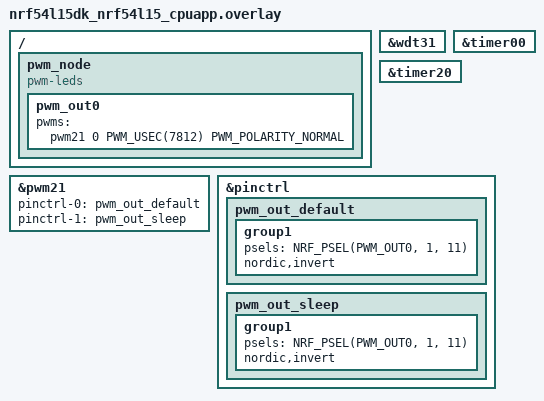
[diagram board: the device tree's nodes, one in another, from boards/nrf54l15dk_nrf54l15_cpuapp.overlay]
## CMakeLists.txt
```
#
# Copyright (c) 2018 Nordic Semiconductor
#
# SPDX-License-Identifier: LicenseRef-Nordic-5-Clause
#
cmake_minimum_required(VERSION 3.20.0)

find_package(Zephyr REQUIRED HINTS $ENV{ZEPHYR_BASE})
project(lesson_4_e2_solution)

set(SOURCES src/main.c)

if (CONFIG_PWM)
    list(APPEND SOURCES src/periph_pwm.c)
endif()

if( CONFIG_NRFX_PWM_GRTC )
    list(APPEND SOURCES src/grtc_pwm.c)
endif()

if( CONFIG_WATCHDOG )
    list(APPEND SOURCES src/wdg_conf.c)
endif()

if(CONFIG_NRFX_TIMER)
    list(APPEND SOURCES src/timer_conf.c)
endif(CONFIG_NRFX_TIMER)

target_include_directories(app PRIVATE inc)
target_sources(app PRIVATE ${SOURCES} )
```

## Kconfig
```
#
# Copyright (c) 2018 Nordic Semiconductor
#
# SPDX-License-Identifier: LicenseRef-Nordic-5-Clause
#

source "Kconfig.zephyr"

menu "Lesson 4 Exercise 2 config"

config PWM_DUTY_CYCLE
	depends on  PWM || NRFX_PWM_GRTC
	int "PWM duty cycle in %"
	default 25

config NRFX_PWM_GRTC
	bool "Use GRTC for PWM"
	default n

config NRFX_TIMER00_1MHz
	bool "Use TIMER00 at 1MHz"
	default n
	select NRFX_TIMER

config NRFX_TIMER00_128MHz
	bool "Use TIMER00 at 128MHz"
	default n
	select NRFX_TIMER

config NRFX_TIMER20_1MHz
	bool "Use TIMER20 at 1MHz"
	default n
	select NRFX_TIMER

endmenu
```

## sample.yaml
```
sample:
  description: Designing Low Power Bluetooth LE devices Lesson 4 Exercise 2
  name: Low Power Bluetooth LE devices - Lesson 4 Exercise 2 

common: 
    sysbuild: true
    build_only: true

    integration_platforms:
      - nrf54l15dk/nrf54l15/cpuapp
      - nrf54l15dk/nrf54l10/cpuapp
      - nrf54l15dk/nrf54l05/cpuapp
      - nrf54lm20dk/nrf54lm20a/cpuapp
      - nrf54lm20dk/nrf54lm20b/cpuapp
      - nrf54ls05dk/nrf54ls05b/cpuapp
      - nrf54lv10dk/nrf54lv10a/cpuapp
      - nrf54lc10dk/nrf54lc10a/cpuapp
    platform_allow:
      - nrf54l15dk/nrf54l15/cpuapp
      - nrf54l15dk/nrf54l10/cpuapp
      - nrf54l15dk/nrf54l05/cpuapp
      - nrf54lm20dk/nrf54lm20a/cpuapp
      - nrf54lm20dk/nrf54lm20b/cpuapp
      - nrf54ls05dk/nrf54ls05b/cpuapp
      - nrf54lv10dk/nrf54lv10a/cpuapp
      - nrf54lc10dk/nrf54lc10a/cpuapp

tests:
  l4.e2.sol: {} 
  
```

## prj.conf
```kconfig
#
# Copyright (c) 2018 Nordic Semiconductor
#
# SPDX-License-Identifier: LicenseRef-Nordic-5-Clause
#

# Logging
CONFIG_LOG=n
CONFIG_SERIAL=n
CONFIG_UART_CONSOLE=n

# Floating Point Unit
CONFIG_FPU=y

# Memory
CONFIG_MAIN_STACK_SIZE=4096
CONFIG_HEAP_MEM_POOL_SIZE=2048
CONFIG_SYSTEM_WORKQUEUE_STACK_SIZE=2048

CONFIG_BT=y
CONFIG_BT_PERIPHERAL=y
CONFIG_BT_DEVICE_NAME="DevAcademy_L4E2"
CONFIG_BT_MAX_CONN=1
CONFIG_BT_MAX_PAIRED=1
CONFIG_BT_USER_PHY_UPDATE=y

# Enable the NUS service
CONFIG_BT_NUS=y
CONFIG_BT_NUS_SECURITY_ENABLED=n

# Enable bonding
CONFIG_BT_SETTINGS=y
CONFIG_FLASH=y
CONFIG_FLASH_PAGE_LAYOUT=y
CONFIG_FLASH_MAP=y
CONFIG_BT_RX_STACK_SIZE=2048
CONFIG_BT_BUF_CMD_TX_COUNT=2

# STEP 4.1 - Enable automatic update of connection parameters
CONFIG_BT_GAP_AUTO_UPDATE_CONN_PARAMS=y

# STEP 4.2 - Set the preferred connection parameters
CONFIG_BT_PERIPHERAL_PREF_MIN_INT=800
CONFIG_BT_PERIPHERAL_PREF_MAX_INT=800
CONFIG_BT_PERIPHERAL_PREF_LATENCY=0
CONFIG_BT_PERIPHERAL_PREF_TIMEOUT=400

# STEP 7.1 - Update data length and MTU
CONFIG_BT_GATT_CLIENT=y
CONFIG_BT_USER_DATA_LEN_UPDATE=y
CONFIG_BT_CTLR_DATA_LENGTH_MAX=251
CONFIG_BT_BUF_ACL_TX_SIZE=251
CONFIG_BT_BUF_ACL_RX_SIZE=251
CONFIG_BT_L2CAP_TX_MTU=247
```

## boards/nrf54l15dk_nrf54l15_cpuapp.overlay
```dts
/ { pwm_node:pwm_node{
        compatible= "pwm-leds";
        pwm_out0: pwm_out0 {
            pwms = <&pwm21 0 PWM_USEC(7812) PWM_POLARITY_NORMAL>;
        };
};
};

&wdt31 {
	status = "okay";
};

 &timer00 {
    status = "okay";
};

 &timer20 {
    status = "okay";
};


&pwm21 {
    status = "okay";
    pinctrl-0 = <&pwm_out_default>;
    pinctrl-1 = <&pwm_out_sleep>;
    pinctrl-names = "default", "sleep";
};

&pinctrl {
    pwm_out_default: pwm_out_default {
        group1 {
            psels = <NRF_PSEL(PWM_OUT0, 1, 11)>;
            nordic,invert;
        };
    };

    pwm_out_sleep: pwm_out_sleep {
        group1 {
            psels = <NRF_PSEL(PWM_OUT0, 1, 11)>;
            nordic,invert;
        };
    };
};
```

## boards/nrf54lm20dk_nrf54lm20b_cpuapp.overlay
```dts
/*
 * Copyright (c) 2025 Nordic Semiconductor ASA
 *
 * SPDX-License-Identifier: LicenseRef-Nordic-5-Clause
 */

/ {
    chosen {
        nordic,nus-uart = &uart20;
    };
};
```

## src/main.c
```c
/*
 * Copyright (c) 2018 Nordic Semiconductor ASA
 *
 * SPDX-License-Identifier: LicenseRef-Nordic-5-Clause
 */

#include <zephyr/types.h>
#include <stddef.h>
#include <string.h>
#include <errno.h>
#include <zephyr/sys/printk.h>
#include <zephyr/sys/byteorder.h>
#include <zephyr/kernel.h>

#include <zephyr/device.h>
#include <zephyr/drivers/gpio.h>
#include <soc.h>

#include <zephyr/bluetooth/bluetooth.h>
#include <zephyr/bluetooth/hci.h>
#include <zephyr/bluetooth/conn.h>
#include <zephyr/bluetooth/uuid.h>
#include <zephyr/bluetooth/gatt.h>

#include <bluetooth/services/lbs.h>

#include <zephyr/settings/settings.h>

#if CONFIG_WATCHDOG
    #include <zephyr/drivers/watchdog.h>
#endif

#if CONFIG_NRFX_TIMER
    #include <nrfx_timer.h>
    #define TIMER_INST_IDX 20
    static nrfx_timer_t timer_inst = NRFX_TIMER_INSTANCE(NRF_TIMER_INST_GET(TIMER_INST_IDX));

#endif  

#if CONFIG_NRFX_PWM_GRTC
    #include <nrfx_grtc.h>
    #include <hal/nrf_gpio.h>
    #define GRTC_PWM_PIN 0x03
    #define GRTC_PWM_PULSE (255/4) 
#endif

#if CONFIG_PWM
    #include <zephyr/drivers/pwm.h>
    #define PWM_PERIOD  PWM_USEC(7812)
    #define PWM_PULSE  ( ( PWM_PERIOD) / 4 ) 
    static const struct pwm_dt_spec pwm_led0 = PWM_DT_SPEC_GET(DT_NODELABEL(pwm_out0));
#endif

#define DEVICE_NAME             CONFIG_BT_DEVICE_NAME
#define DEVICE_NAME_LEN         (sizeof(DEVICE_NAME) - 1)

#define RANDOM_BYTES_COUNT      16

#define RUN_STATUS_LED          DK_LED1
#define CON_STATUS_LED          DK_LED2
#define RUN_LED_BLINK_INTERVAL  1000

#define USER_LED                DK_LED3

#define USER_BUTTON             DK_BTN1_MSK

#define BT_LE_ADV_CONN_1000                                                                      \
    BT_LE_ADV_PARAM(BT_LE_ADV_OPT_CONN, BT_GAP_ADV_SLOW_INT_MIN, BT_GAP_ADV_SLOW_INT_MIN,  \
            NULL)

static bool app_button_state;
static struct k_work adv_work;

static const struct bt_data ad[] = {
    BT_DATA_BYTES(BT_DATA_FLAGS, (BT_LE_AD_GENERAL | BT_LE_AD_NO_BREDR)),
    BT_DATA(BT_DATA_NAME_COMPLETE, DEVICE_NAME, DEVICE_NAME_LEN),
};

static const struct bt_data sd[] = {
    BT_DATA_BYTES(BT_DATA_UUID128_ALL, BT_UUID_LBS_VAL),
};

static void adv_work_handler(struct k_work *work)
{
    int err = bt_le_adv_start(BT_LE_ADV_CONN_1000, ad, ARRAY_SIZE(ad), sd, ARRAY_SIZE(sd));

    if (err) {
        printk("Advertising failed to start (err %d)\n", err);
        return;
    }

    printk("Advertising successfully started\n");
}

static void advertising_start(void)
{
    k_work_submit(&adv_work);
}

static void connected(struct bt_conn *conn, uint8_t err)
{
    if (err) {
        printk("Connection failed, err 0x%02x %s\n", err, bt_hci_err_to_str(err));
        return;
    }

    printk("Connected\n");
}

static void disconnected(struct bt_conn *conn, uint8_t reason)
{
    printk("Disconnected, reason 0x%02x %s\n", reason, bt_hci_err_to_str(reason));
}


static void recycled_cb(void)
{
    printk("Connection object available from previous conn. Disconnect is complete!\n");
    advertising_start();
}

#ifdef CONFIG_BT_LBS_SECURITY_ENABLED
static void security_changed(struct bt_conn *conn, bt_security_t level,
                 enum bt_security_err err)
{
    char addr[BT_ADDR_LE_STR_LEN];

    bt_addr_le_to_str(bt_conn_get_dst(conn), addr, sizeof(addr));

    if (!err) {
        printk("Security changed: %s level %u\n", addr, level);
    } else {
        printk("Security failed: %s level %u err %d %s\n", addr, level, err,
               bt_security_err_to_str(err));
    }
}
#endif

BT_CONN_CB_DEFINE(conn_callbacks) = {
    .connected        = connected,
    .disconnected     = disconnected,
    .recycled         = recycled_cb,
#ifdef CONFIG_BT_LBS_SECURITY_ENABLED
    .security_changed = security_changed,
#endif
};

#if defined(CONFIG_BT_LBS_SECURITY_ENABLED)
static void auth_passkey_display(struct bt_conn *conn, unsigned int passkey)
{
    char addr[BT_ADDR_LE_STR_LEN];

    bt_addr_le_to_str(bt_conn_get_dst(conn), addr, sizeof(addr));

    printk("Passkey for %s: %06u\n", addr, passkey);
}

static void auth_cancel(struct bt_conn *conn)
{
    char addr[BT_ADDR_LE_STR_LEN];

    bt_addr_le_to_str(bt_conn_get_dst(conn), addr, sizeof(addr));

    printk("Pairing cancelled: %s\n", addr);
}

static void pairing_complete(struct bt_conn *conn, bool bonded)
{
    char addr[BT_ADDR_LE_STR_LEN];

    bt_addr_le_to_str(bt_conn_get_dst(conn), addr, sizeof(addr));

    printk("Pairing completed: %s, bonded: %d\n", addr, bonded);
}

static void pairing_failed(struct bt_conn *conn, enum bt_security_err reason)
{
    char addr[BT_ADDR_LE_STR_LEN];

    bt_addr_le_to_str(bt_conn_get_dst(conn), addr, sizeof(addr));

    printk("Pairing failed conn: %s, reason %d %s\n", addr, reason,
           bt_security_err_to_str(reason));
}

static struct bt_conn_auth_cb conn_auth_callbacks = {
    .passkey_display = auth_passkey_display,
    .cancel = auth_cancel,
};

static struct bt_conn_auth_info_cb conn_auth_info_callbacks = {
    .pairing_complete = pairing_complete,
    .pairing_failed = pairing_failed
};
#else
static struct bt_conn_auth_cb conn_auth_callbacks;
static struct bt_conn_auth_info_cb conn_auth_info_callbacks;
#endif

static void app_led_cb(bool led_state)
{

}

static bool app_button_cb(void)
{
    return app_button_state;
}

static struct bt_lbs_cb lbs_callbacs = {
    .led_cb    = app_led_cb,
    .button_cb = app_button_cb,
};


#if CONFIG_WATCHDOG
 
#ifndef WDT_MAX_WINDOW
#define WDT_MAX_WINDOW  5000U
#endif

#ifndef WDT_MIN_WINDOW
#define WDT_MIN_WINDOW  0U
#endif


static struct wdt_timeout_cfg wdt_config = {
        .window = {
            .min = WDT_MIN_WINDOW,
            .max = WDT_MAX_WINDOW
        },
        .callback = NULL,
        .flags = WDT_FLAG_RESET_SOC
};

static int init_watchdog(const struct device * wdt)
{
    int wdt_channel_id;
    int err = -1;
    printk("Watchdog sample application\n");

    if (!device_is_ready(wdt)) {
        printk("%s: device not ready.\n", wdt->name);
        return err;
    }

    wdt_channel_id = wdt_install_timeout(wdt, &wdt_config);
    if (wdt_channel_id == -ENOTSUP) {
        /* IWDG driver for STM32 doesn't support callback */
        printk("Callback support rejected, continuing anyway\n");
        wdt_config.callback = NULL;
        wdt_channel_id = wdt_install_timeout(wdt, &wdt_config);
    }
    if (wdt_channel_id < 0) {
        printk("Watchdog install error\n");
        return wdt_channel_id;
    }

    err = wdt_setup(wdt, WDT_OPT_PAUSE_HALTED_BY_DBG);
    if (err < 0) {
        printk("Watchdog setup error\n");
        return err;
    }
    
    wdt_feed(wdt, wdt_channel_id);

    return wdt_channel_id;
}
#endif

#if CONFIG_NRFX_PWM_GRTC
static void set_grtc_pwm(uint8_t duty_cycle)
{
    nrf_gpio_pin_control_select(GRTC_PWM_PIN, NRF_GPIO_PIN_SEL_GRTC);
    nrf_grtc_pwm_compare_set(NRF_GRTC, duty_cycle);
    nrf_grtc_task_trigger(NRF_GRTC, NRF_GRTC_TASK_PWM_START);
}
#endif

#if CONFIG_NRFX_TIMER
static void enable_timer(nrfx_timer_t * timer, uint32_t frequency_mhz)
{
     nrfx_timer_config_t config = NRFX_TIMER_DEFAULT_CONFIG(NRFX_MHZ_TO_HZ(frequency_mhz));
    config.bit_width = NRF_TIMER_BIT_WIDTH_32;
    config.p_context = "Some context";

    if(nrfx_timer_init(timer, &config, NULL) != 0)
    {
        return;
    }
    nrfx_timer_clear(timer);
    nrfx_timer_enable(timer);
}
#endif

int main(void)
{
    int err;

    #if CONFIG_NRFX_PWM_GRTC
        set_grtc_pwm(GRTC_PWM_PULSE);   
    #endif    

    #if CONFIG_PWM
        pwm_set_dt(&pwm_led0, PWM_PERIOD, PWM_PULSE);
    #endif

    printk("Starting Bluetooth Peripheral LBS sample\n");

    if (IS_ENABLED(CONFIG_BT_LBS_SECURITY_ENABLED)) {
        err = bt_conn_auth_cb_register(&conn_auth_callbacks);
        if (err) {
            printk("Failed to register authorization callbacks.\n");
            return 0;
        }

        err = bt_conn_auth_info_cb_register(&conn_auth_info_callbacks);
        if (err) {
            printk("Failed to register authorization info callbacks.\n");
            return 0;
        }
    }

    err = bt_enable(NULL);
    if (err) {
        printk("Bluetooth init failed (err %d)\n", err);
        return 0;
    }

    printk("Bluetooth initialized\n");

    if (IS_ENABLED(CONFIG_SETTINGS)) {
        settings_load();
    }

    err = bt_lbs_init(&lbs_callbacs);
    if (err) {
        printk("Failed to init LBS (err:%d)\n", err);
        return 0;
    }

    k_work_init(&adv_work, adv_work_handler);
    advertising_start();

    //WDG
#if CONFIG_WATCHDOG
    const struct device *const wdt = DEVICE_DT_GET(DT_ALIAS(watchdog0));
    int wdt_channel_id = init_watchdog(wdt);

    if(wdt_channel_id <0) {
        printk("Failed to initialize watchdog (err %d)\n", wdt_channel_id);
        return 0;
    }
#endif


#if CONFIG_NRFX_TIMER
    //TIMER
    IRQ_CONNECT(NRFX_IRQ_NUMBER_GET(NRF_TIMER_INST_GET(TIMER_INST_IDX)), IRQ_PRIO_LOWEST,
    nrfx_timer_irq_handler, &timer_inst, 20);
    enable_timer(&timer_inst, 1);

#endif

    while (1) 
    {
        #if CONFIG_WATCHDOG
        wdt_feed(wdt, wdt_channel_id);
        #endif
        k_sleep(K_MSEC(1000));
    }
}
```

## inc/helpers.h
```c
#ifndef L4_E2_SOL_INC_HELPERS_H
#define L4_E2_SOL_INC_HELPERS_H

#include <zephyr/kernel.h>
#include <zephyr/device.h>

#if defined(CONFIG_WATCHDOG)

/* @brief Initialize the watchdog timer */
int init_watchdog();

/* @brief Feed the watchdog timer */    
void watchdog_feed();
#endif

#if defined(CONFIG_NRFX_PWM_GRTC)

/* @brief Set the GRTC PWM duty cycle   
    @param duty_cycle The duty cycle value in %
***/
void set_grtc_pwm(uint8_t duty_cycle);  
#endif


#if defined(CONFIG_NRFX_TIMER) 

#define TIMER_1MHZ (1)
#define TIMER_128MHZ (128)

#endif

#if defined(CONFIG_NRFX_TIMER00_1MHz) || defined(CONFIG_NRFX_TIMER00_128MHz)

/* @brief Enable TIMER00 with the specified frequency
    @param frequency_mhz The frequency in MHz
***/
void enable_timer00( uint32_t frequency_mhz);
#endif

#if defined(CONFIG_NRFX_TIMER20_1MHz)

/* @brief Enable TIMER20 with the specified frequency
    @param frequency_mhz The frequency in MHz
***/
void enable_timer20( uint32_t frequency_mhz);
#endif

#if defined(CONFIG_PWM)

/* @brief Set the PWM output duty cycle
    @param duty_cycle The duty cycle value in %
***/
int set_pwm_out(uint8_t duty_cycle);
#endif

#endif      /* L4_E2_SOL_INC_HELPERS_H */
```

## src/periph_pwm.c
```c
#include <zephyr/drivers/pwm.h>
#include <helpers.h>

#define PWM_PERIOD  PWM_USEC(7812)

static const struct pwm_dt_spec pwm_led0 = PWM_DT_SPEC_GET(DT_NODELABEL(pwm_out0));

int set_pwm_out(uint8_t duty_cycle)
{
    int err;
    if (!pwm_is_ready_dt(&pwm_led0)) {
        printk("PWM device is not ready\n");
        return -ENODEV;
    }

    err = pwm_set_dt(&pwm_led0, PWM_PERIOD, ( duty_cycle * PWM_PERIOD ) / 100);
    if (err) {
        printk("Error %d: failed to set PWM\n", err);
        return err;
    }

    return 0;
}
```

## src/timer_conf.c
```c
#include <nrfx_timer.h>
#include <helpers.h>



#if defined(CONFIG_NRFX_TIMER00_1MHz) || defined(CONFIG_NRFX_TIMER00_128MHz)
#define TIMER00_INST_IDX 00
static nrfx_timer_t timer00_inst = NRFX_TIMER_INSTANCE(NRF_TIMER_INST_GET(TIMER00_INST_IDX));
#endif

#if defined(CONFIG_NRFX_TIMER20_1MHz)
#define TIMER20_INST_IDX 20
static nrfx_timer_t timer20_inst = NRFX_TIMER_INSTANCE(NRF_TIMER_INST_GET(TIMER20_INST_IDX));
#endif


static void init_timer(nrfx_timer_t *timer, uint32_t frequency_mhz)
{
    nrfx_timer_config_t config = NRFX_TIMER_DEFAULT_CONFIG(NRFX_MHZ_TO_HZ(frequency_mhz));
    config.bit_width = NRF_TIMER_BIT_WIDTH_32;
    config.p_context = "Some context";

    if(nrfx_timer_init(timer, &config, NULL) != 0)
    {
        return;
    }

    nrfx_timer_clear(timer);
    nrfx_timer_enable(timer);
}


#if defined(CONFIG_NRFX_TIMER00_1MHz) || defined(CONFIG_NRFX_TIMER00_128MHz)
void enable_timer00( uint32_t frequency_mhz)
{

    IRQ_CONNECT(NRFX_IRQ_NUMBER_GET(NRF_TIMER_INST_GET(TIMER00_INST_IDX)), IRQ_PRIO_LOWEST,
    nrfx_timer_irq_handler, &timer00_inst, 0);
    
    init_timer(&timer00_inst, frequency_mhz);
}
#endif

#if defined(CONFIG_NRFX_TIMER20_1MHz)
void enable_timer20( uint32_t frequency_mhz)
{
    IRQ_CONNECT(NRFX_IRQ_NUMBER_GET(NRF_TIMER_INST_GET(TIMER20_INST_IDX)), IRQ_PRIO_LOWEST,
    nrfx_timer_irq_handler, &timer20_inst, 20);
    
    init_timer(&timer20_inst, frequency_mhz);
}
#endif
```
